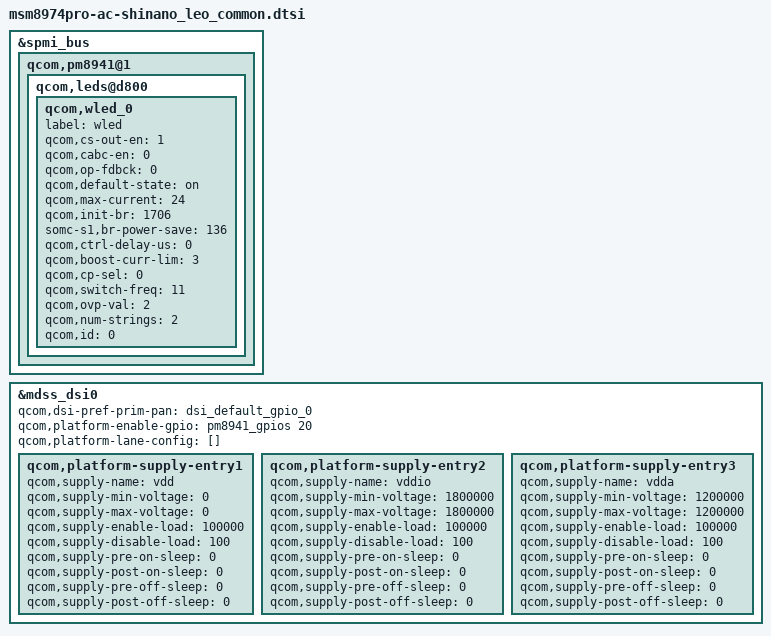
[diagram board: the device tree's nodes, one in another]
/* arch/arm/boot/dts/msm8974pro-ac-shinano_leo_common.dtsi
 *
 * Copyright (C) 2015 Sony Mobile Communications Inc.
 *
 * This program is free software; you can redistribute it and/or modify
 * it under the terms of the GNU General Public License version 2 and
 * only version 2 as published by the Free Software Foundation.
 *
 * This program is distributed in the hope that it will be useful,
 * but WITHOUT ANY WARRANTY; without even the implied warranty of
 * MERCHANTABILITY or FITNESS FOR A PARTICULAR PURPOSE.  See the
 * GNU General Public License for more details.
 *
 *
 * NOTE: This file has been modified by Sony Mobile Communications Inc.
 * Modifications are licensed under the License.
 */

// [...]
&spmi_bus {
	qcom,pm8941@1 {
		// [...]
		qcom,leds@d800 {
			status = "okay";
			qcom,wled_0 {
				label = "wled";
				//linux,name = "wled:backlight";
				//linux,default-trigger = "bkl-trigger";
				qcom,cs-out-en = <1>;
				qcom,cabc-en = <0>;
				qcom,op-fdbck = <0>;
				qcom,default-state = "on";
				qcom,max-current = <24>;
				qcom,init-br = <1706>;
				somc-s1,br-power-save = <136>;
				qcom,ctrl-delay-us = <0>;
				qcom,boost-curr-lim = <3>;
				qcom,cp-sel = <0>;
				qcom,switch-freq = <11>;
				qcom,ovp-val = <2>;
				qcom,num-strings = <2>;
				qcom,id = <0>;
				// [...]
			};
		};
	};
};

&mdss_dsi0 {
	qcom,dsi-pref-prim-pan = <&dsi_default_gpio_0>;
	//vdd-supply = <&pm8941_lvs3>;
	qcom,platform-enable-gpio = <&pm8941_gpios 20 0>;
	qcom,platform-lane-config = [];
	qcom,platform-supply-entry1 {
			qcom,supply-name = "vdd";
			qcom,supply-min-voltage = <0>;
			qcom,supply-max-voltage = <0>;
			qcom,supply-enable-load = <100000>;
			qcom,supply-disable-load = <100>;
			qcom,supply-pre-on-sleep = <0>;
			qcom,supply-post-on-sleep = <0>;
			qcom,supply-pre-off-sleep = <0>;
			qcom,supply-post-off-sleep = <0>;
	};
	qcom,platform-supply-entry2 {
			qcom,supply-name = "vddio";
			qcom,supply-min-voltage = <1800000>;
			qcom,supply-max-voltage = <1800000>;
			qcom,supply-enable-load = <100000>;
			qcom,supply-disable-load = <100>;
			qcom,supply-pre-on-sleep = <0>;
			qcom,supply-post-on-sleep = <0>;
			qcom,supply-pre-off-sleep = <0>;
			qcom,supply-post-off-sleep = <0>;
	};
	qcom,platform-supply-entry3 {
			qcom,supply-name = "vdda";
			qcom,supply-min-voltage = <1200000>;
			qcom,supply-max-voltage = <1200000>;
			qcom,supply-enable-load = <100000>;
			qcom,supply-disable-load = <100>;
			qcom,supply-pre-on-sleep = <0>;
			qcom,supply-post-on-sleep = <0>;
			qcom,supply-pre-off-sleep = <0>;
			qcom,supply-post-off-sleep = <0>;
	};
};
